# PIC32MX274F256D register map
Registers are 32-bit, access not given, reset 0x0 unless marked. A register's access mark holds for its fields unless they carry their own. Offsets are from the block's base; [hi:lo] are bit positions; 'fields as' and 'values as' point back to an identical list.

## DMAC2 — DMAC2 peripheral
Base 0xBF8831E0
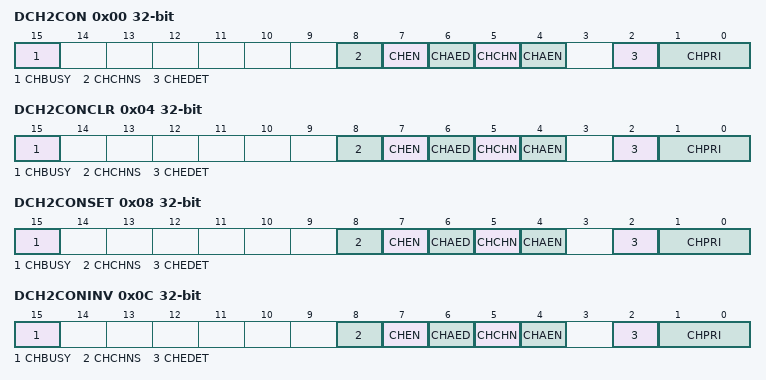
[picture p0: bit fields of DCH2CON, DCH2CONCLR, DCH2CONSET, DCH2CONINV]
0x00 DCH2CON
  [15] CHBUSY, [8] CHCHNS, [7] CHEN, [6] CHAED, [5] CHCHN, [4] CHAEN, [2] CHEDET, [1:0] CHPRI
0x04 DCH2CONCLR
  fields as DCH2CON
0x08 DCH2CONSET
  fields as DCH2CON
0x0C DCH2CONINV
  fields as DCH2CON
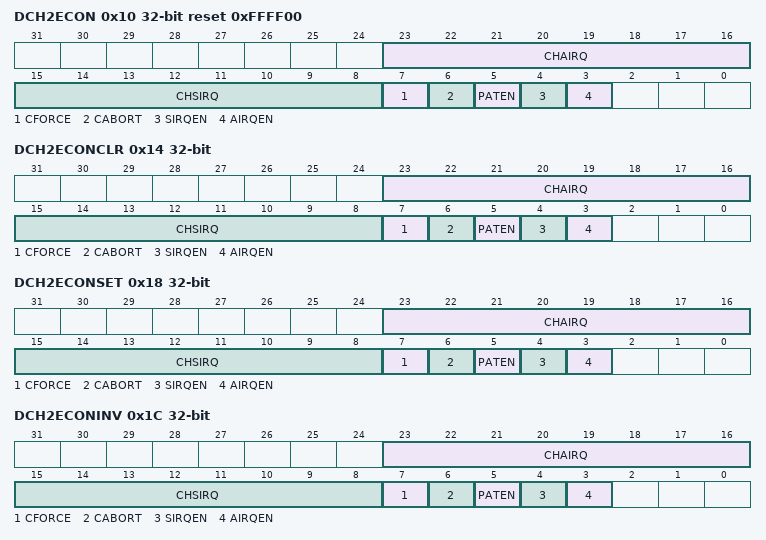
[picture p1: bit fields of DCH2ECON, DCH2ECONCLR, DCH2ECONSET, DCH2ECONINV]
0x10 DCH2ECON reset 0xFFFF00
  [23:16] CHAIRQ, [15:8] CHSIRQ, [7] CFORCE, [6] CABORT, [5] PATEN, [4] SIRQEN, [3] AIRQEN
0x14 DCH2ECONCLR
  fields as DCH2ECON
0x18 DCH2ECONSET
  fields as DCH2ECON
0x1C DCH2ECONINV
  fields as DCH2ECON
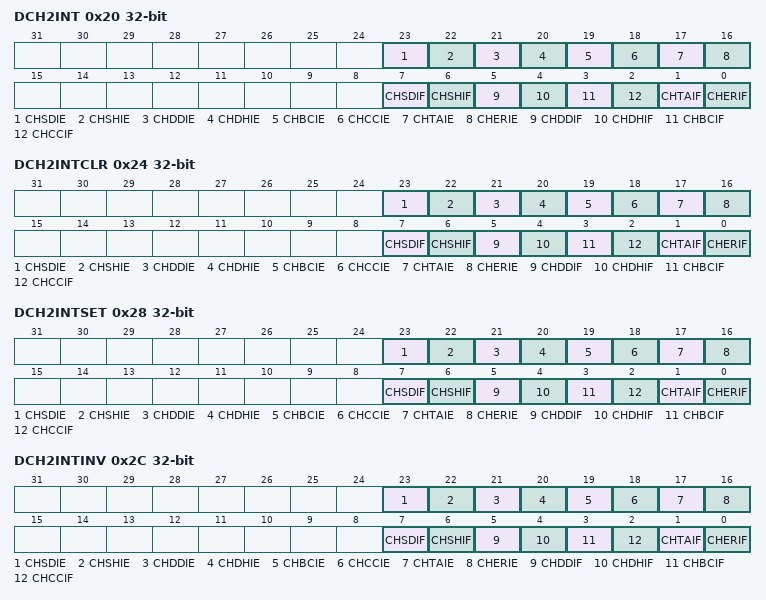
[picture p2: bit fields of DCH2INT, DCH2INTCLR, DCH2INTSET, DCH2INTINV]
0x20 DCH2INT
  [23] CHSDIE, [22] CHSHIE, [21] CHDDIE, [20] CHDHIE, [19] CHBCIE, [18] CHCCIE, [17] CHTAIE, [16] CHERIE, [7] CHSDIF, [6] CHSHIF, [5] CHDDIF, [4] CHDHIF, [3] CHBCIF, [2] CHCCIF, [1] CHTAIF, [0] CHERIF
0x24 DCH2INTCLR
  fields as DCH2INT
0x28 DCH2INTSET
  fields as DCH2INT
0x2C DCH2INTINV
  fields as DCH2INT
0x30 DCH2SSA
0x34 DCH2SSACLR
  [31:0] DCH2SSA
0x38 DCH2SSASET
  [31:0] DCH2SSA
0x3C DCH2SSAINV
  [31:0] DCH2SSA
0x40 DCH2DSA
0x44 DCH2DSACLR
  [31:0] DCH2DSA
0x48 DCH2DSASET
  [31:0] DCH2DSA
0x4C DCH2DSAINV
  [31:0] DCH2DSA
0x50 DCH2SSIZ
  [15:0] CHSSIZ
0x54 DCH2SSIZCLR
  [15:0] CHSSIZ
0x58 DCH2SSIZSET
  [15:0] CHSSIZ
0x5C DCH2SSIZINV
  [15:0] CHSSIZ
0x60 DCH2DSIZ
  [15:0] CHDSIZ
0x64 DCH2DSIZCLR
  [15:0] CHDSIZ
0x68 DCH2DSIZSET
  [15:0] CHDSIZ
0x6C DCH2DSIZINV
  [15:0] CHDSIZ
0x70 DCH2SPTR
  [15:0] CHSPTR
0x74 DCH2SPTRCLR
  [15:0] CHSPTR
0x78 DCH2SPTRSET
  [15:0] CHSPTR
0x7C DCH2SPTRINV
  [15:0] CHSPTR
0x80 DCH2DPTR
  [15:0] CHDPTR
0x84 DCH2DPTRCLR
  [15:0] CHDPTR
0x88 DCH2DPTRSET
  [15:0] CHDPTR
0x8C DCH2DPTRINV
  [15:0] CHDPTR
0x90 DCH2CSIZ
  [15:0] CHCSIZ
0x94 DCH2CSIZCLR
  [15:0] CHCSIZ
0x98 DCH2CSIZSET
  [15:0] CHCSIZ
0x9C DCH2CSIZINV
  [15:0] CHCSIZ
0xA0 DCH2CPTR
  [15:0] CHCPTR
0xA4 DCH2CPTRCLR
  [15:0] CHCPTR
0xA8 DCH2CPTRSET
  [15:0] CHCPTR
0xAC DCH2CPTRINV
  [15:0] CHCPTR
0xB0 DCH2DAT
  [7:0] DCHPDAT
0xB4 DCH2DATCLR
  [7:0] DCHPDAT
0xB8 DCH2DATSET
  [7:0] DCHPDAT
0xBC DCH2DATINV
  [7:0] DCHPDAT

## DMAC3 — DMAC3 peripheral
Base 0xBF8832A0
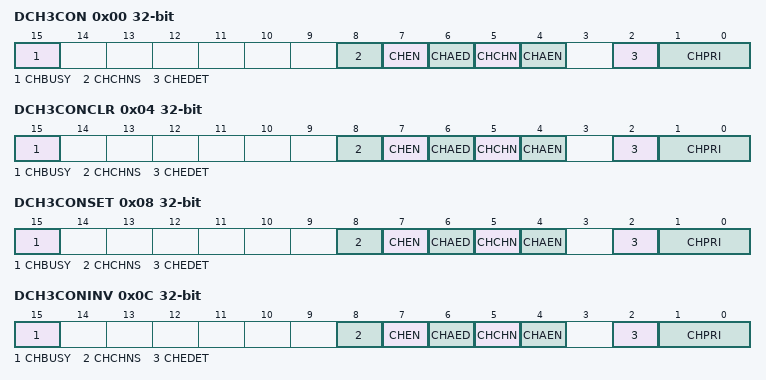
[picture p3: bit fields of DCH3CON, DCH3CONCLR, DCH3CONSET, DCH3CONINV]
0x00 DCH3CON
  [15] CHBUSY, [8] CHCHNS, [7] CHEN, [6] CHAED, [5] CHCHN, [4] CHAEN, [2] CHEDET, [1:0] CHPRI
0x04 DCH3CONCLR
  fields as DCH3CON
0x08 DCH3CONSET
  fields as DCH3CON
0x0C DCH3CONINV
  fields as DCH3CON
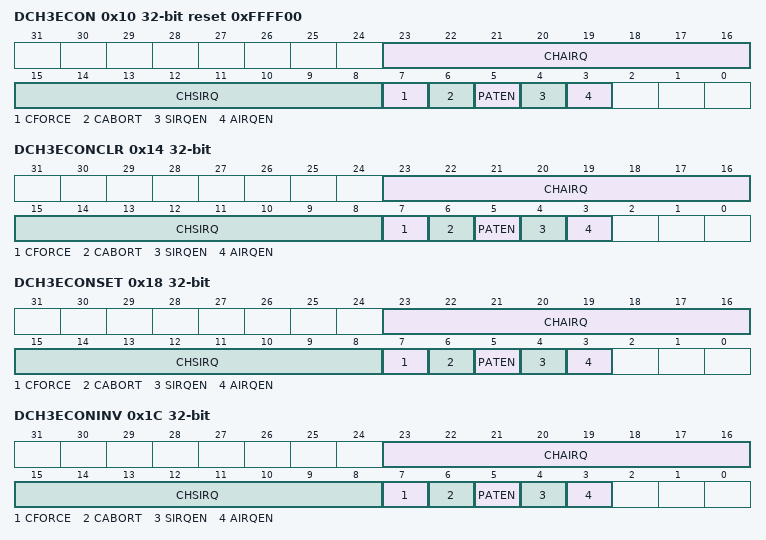
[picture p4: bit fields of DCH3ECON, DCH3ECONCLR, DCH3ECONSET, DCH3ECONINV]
0x10 DCH3ECON reset 0xFFFF00
  [23:16] CHAIRQ, [15:8] CHSIRQ, [7] CFORCE, [6] CABORT, [5] PATEN, [4] SIRQEN, [3] AIRQEN
0x14 DCH3ECONCLR
  fields as DCH3ECON
0x18 DCH3ECONSET
  fields as DCH3ECON
0x1C DCH3ECONINV
  fields as DCH3ECON
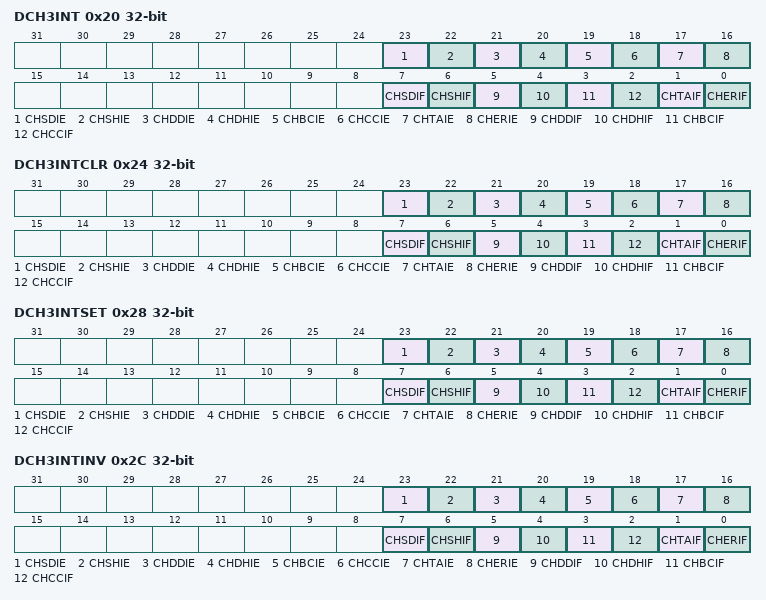
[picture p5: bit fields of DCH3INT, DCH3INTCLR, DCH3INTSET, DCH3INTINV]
0x20 DCH3INT
  [23] CHSDIE, [22] CHSHIE, [21] CHDDIE, [20] CHDHIE, [19] CHBCIE, [18] CHCCIE, [17] CHTAIE, [16] CHERIE, [7] CHSDIF, [6] CHSHIF, [5] CHDDIF, [4] CHDHIF, [3] CHBCIF, [2] CHCCIF, [1] CHTAIF, [0] CHERIF
0x24 DCH3INTCLR
  fields as DCH3INT
0x28 DCH3INTSET
  fields as DCH3INT
0x2C DCH3INTINV
  fields as DCH3INT
0x30 DCH3SSA
0x34 DCH3SSACLR
  [31:0] DCH3SSA
0x38 DCH3SSASET
  [31:0] DCH3SSA
0x3C DCH3SSAINV
  [31:0] DCH3SSA
0x40 DCH3DSA
0x44 DCH3DSACLR
  [31:0] DCH3DSA
0x48 DCH3DSASET
  [31:0] DCH3DSA
0x4C DCH3DSAINV
  [31:0] DCH3DSA
0x50 DCH3SSIZ
  [15:0] CHSSIZ
0x54 DCH3SSIZCLR
  [15:0] CHSSIZ
0x58 DCH3SSIZSET
  [15:0] CHSSIZ
0x5C DCH3SSIZINV
  [15:0] CHSSIZ
0x60 DCH3DSIZ
  [15:0] CHDSIZ
0x64 DCH3DSIZCLR
  [15:0] CHDSIZ
0x68 DCH3DSIZSET
  [15:0] CHDSIZ
0x6C DCH3DSIZINV
  [15:0] CHDSIZ
0x70 DCH3SPTR
  [15:0] CHSPTR
0x74 DCH3SPTRCLR
  [15:0] CHSPTR
0x78 DCH3SPTRSET
  [15:0] CHSPTR
0x7C DCH3SPTRINV
  [15:0] CHSPTR
0x80 DCH3DPTR
  [15:0] CHDPTR
0x84 DCH3DPTRCLR
  [15:0] CHDPTR
0x88 DCH3DPTRSET
  [15:0] CHDPTR
0x8C DCH3DPTRINV
  [15:0] CHDPTR
0x90 DCH3CSIZ
  [15:0] CHCSIZ
0x94 DCH3CSIZCLR
  [15:0] CHCSIZ
0x98 DCH3CSIZSET
  [15:0] CHCSIZ
0x9C DCH3CSIZINV
  [15:0] CHCSIZ
0xA0 DCH3CPTR
  [15:0] CHCPTR
0xA4 DCH3CPTRCLR
  [15:0] CHCPTR
0xA8 DCH3CPTRSET
  [15:0] CHCPTR
0xAC DCH3CPTRINV
  [15:0] CHCPTR
0xB0 DCH3DAT
  [7:0] DCHPDAT
0xB4 DCH3DATCLR
  [7:0] DCHPDAT
0xB8 DCH3DATSET
  [7:0] DCHPDAT
0xBC DCH3DATINV
  [7:0] DCHPDAT
